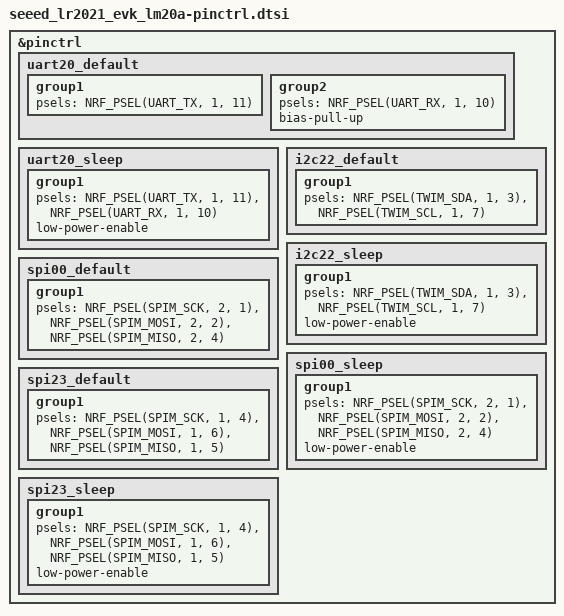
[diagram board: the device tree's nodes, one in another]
/*
 * Semtech LR2021 LoRa Plus EVK on a XIAO nRF54LM20A — pin control
 * Copyright (c) 2026 ZephCore
 * SPDX-License-Identifier: MIT
 *
 * Pin assignments are the XIAO nRF54LM20A's fixed connector mapping, copied
 * from Zephyr's xiao_nrf54lm20a_nrf54lm20a-pinctrl.dtsi. Only the three buses
 * this kit uses are declared:
 *
 *   uart20  P1.11 TX / P1.10 RX  — console, via the SAMD11 CMSIS-DAP bridge
 *   i2c22   P1.03 SDA / P1.07 SCL — D4/D5: OLED + the two I2C Grove ports
 *   spi23   P1.04 SCK / P1.06 MOSI / P1.05 MISO — D8/D10/D9: LR2021
 *   spi00   P2.01 SCK / P2.02 MOSI / P2.04 MISO — the XIAO's 8 MB flash (/ext)
 *
 * uart21 (D6/D7) is deliberately absent — see the DIO7/DIO11 note in the .dts.
 */

&pinctrl {
	/omit-if-no-ref/ uart20_default: uart20_default {
		group1 {
			psels = <NRF_PSEL(UART_TX, 1, 11)>;
		};

		group2 {
			psels = <NRF_PSEL(UART_RX, 1, 10)>;
			bias-pull-up;
		};
	};

	/omit-if-no-ref/ uart20_sleep: uart20_sleep {
		group1 {
			psels = <NRF_PSEL(UART_TX, 1, 11)>,
				<NRF_PSEL(UART_RX, 1, 10)>;
			low-power-enable;
		};
	};

	/omit-if-no-ref/ i2c22_default: i2c22_default {
		group1 {
			psels = <NRF_PSEL(TWIM_SDA, 1, 3)>,
				<NRF_PSEL(TWIM_SCL, 1, 7)>;
		};
	};

	/omit-if-no-ref/ i2c22_sleep: i2c22_sleep {
		group1 {
			psels = <NRF_PSEL(TWIM_SDA, 1, 3)>,
				<NRF_PSEL(TWIM_SCL, 1, 7)>;
			low-power-enable;
		};
	};

	/omit-if-no-ref/ spi00_default: spi00_default {
		group1 {
			psels = <NRF_PSEL(SPIM_SCK, 2, 1)>,
				<NRF_PSEL(SPIM_MOSI, 2, 2)>,
				<NRF_PSEL(SPIM_MISO, 2, 4)>;
		};
	};

	/omit-if-no-ref/ spi00_sleep: spi00_sleep {
		group1 {
			psels = <NRF_PSEL(SPIM_SCK, 2, 1)>,
				<NRF_PSEL(SPIM_MOSI, 2, 2)>,
				<NRF_PSEL(SPIM_MISO, 2, 4)>;
			low-power-enable;
		};
	};

	/omit-if-no-ref/ spi23_default: spi23_default {
		group1 {
			psels = <NRF_PSEL(SPIM_SCK, 1, 4)>,
				<NRF_PSEL(SPIM_MOSI, 1, 6)>,
				<NRF_PSEL(SPIM_MISO, 1, 5)>;
		};
	};

	/omit-if-no-ref/ spi23_sleep: spi23_sleep {
		group1 {
			psels = <NRF_PSEL(SPIM_SCK, 1, 4)>,
				<NRF_PSEL(SPIM_MOSI, 1, 6)>,
				<NRF_PSEL(SPIM_MISO, 1, 5)>;
			low-power-enable;
		};
	};
};
